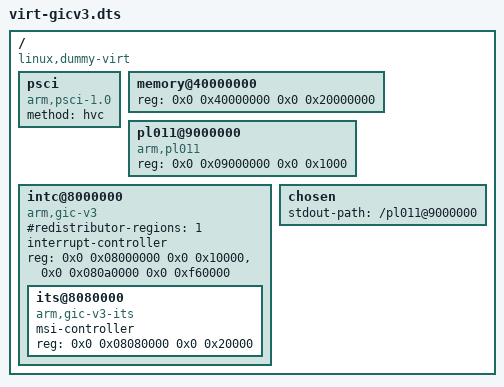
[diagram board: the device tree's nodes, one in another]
// SPDX-License-Identifier: GPL-3.0-or-later
// Copyright (C) 2026 Sergey Subbotin <ssubbotin@gmail.com>
// QEMU 11.1.1 -M virt,gic-version=3 (TCG), cut down to RAM, PSCI, the
// console and the GIC with its ITS.
/dts-v1/;
/ {
	#address-cells = <2>;
	#size-cells = <2>;
	compatible = "linux,dummy-virt";

	psci {
		compatible = "arm,psci-1.0", "arm,psci-0.2", "arm,psci";
		method = "hvc";
	};

	memory@40000000 {
		device_type = "memory";
		reg = <0x0 0x40000000 0x0 0x20000000>;
	};

	pl011@9000000 {
		compatible = "arm,pl011", "arm,primecell";
		reg = <0x0 0x09000000 0x0 0x1000>;
	};

	intc@8000000 {
		compatible = "arm,gic-v3";
		#redistributor-regions = <1>;
		#address-cells = <2>;
		#size-cells = <2>;
		ranges;
		#interrupt-cells = <3>;
		interrupt-controller;
		reg = <0x0 0x08000000 0x0 0x10000>, <0x0 0x080a0000 0x0 0xf60000>;

		its@8080000 {
			compatible = "arm,gic-v3-its";
			msi-controller;
			#msi-cells = <1>;
			reg = <0x0 0x08080000 0x0 0x20000>;
		};
	};

	chosen {
		stdout-path = "/pl011@9000000";
	};
};
